# a34m41x register map
Vendor: ABOV Semiconductor Co., Ltd.; File version: 1.0
CPU: CM4 r0p1, little endian, MPU, FPU, VTOR, 4 interrupt priority bits
Registers are 32-bit, read-write, reset 0x0 unless marked. A register's access mark holds for its fields unless they carry their own. Offsets are from the block's base; [hi:lo] are bit positions; {n}, {i} and the like mark numbered series; 'fields as' and 'values as' point back to an identical list.

## QEI0 — Quadurature Encoder Interface
Base 0x4000B400
Same registers: QEI1 0x4000B500
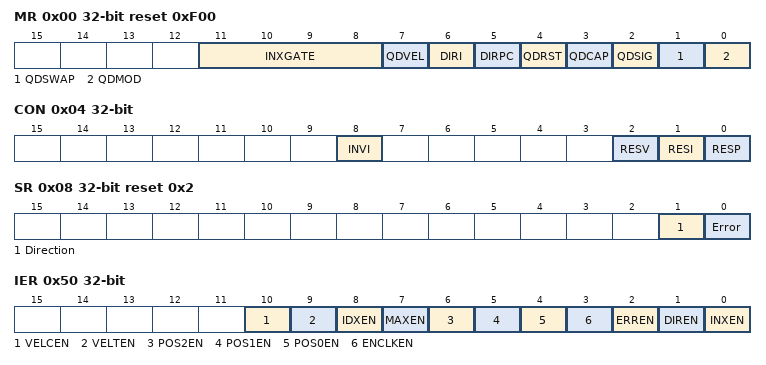
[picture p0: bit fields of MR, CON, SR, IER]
0x00 MR reset 0xF00 — QEI n Mode Register
  [11:8] INXGATE — Index Gating Configuration
    15=ALL_PASS (Pass the index); 8=PhA_0_PhB_0 (Pass the index when Ph-A = 0, Ph-B = 0); 4=PhA_0_PhB_1 (Pass the index when Ph-A = 0, Ph-B = 1); 2=PhA_1_PhB_1 (Pass the index when Ph-A = 1, Ph-B = 1); 1=PhA_1_PhB_0 (Pass the index when Ph-A = 1, Ph-B = 0)
  [7] QDVEL — Velocity Counter Enable Bit
    0=Disable; 1=Enable
  [6] DIRI — Index Counter Direction Control bit
    0=Not_Affect (DI Status Not Affect to the counter); 1=Change_Direction (DIR Status Will Change Count Direction)
  [5] DIRPC — Position Counter Direction Control bit
    values as DIRI
  [4] QDRST — Reset Mode Setting Bit
    0=Maximum_Position (Reset With Maximum Position Reset); 1=Index_Pulse (Reset with index pulse)
  [3] QDCAP — Capture Mode Setting Bit
    0=Only Ph-A Edge is Counted; 1=PhA_PhB (Ph-A and Ph-B Edge are counted)
  [2] QDSIG — Signal Mode Setting Bit
    0=Quadrature phase signal (Ph-A, Ph-B); 1=Clock_Direction (Clock Signal = Ph-A, Direction Signal = Ph-B)
  [1] QDSWAP — QEI Input Signal SWAP Setting Bit
    0=No_Swap; 1=Swap Ph-A and Ph-B
  [0] QDMOD — QEI Module Enable Bit
    0=Disable; 1=Enable
0x04 CON — QEI n Control Register
  [8] INVI — Index Pulse Reverse Setting Bit
    0=None; 1=Reverse (Index Input Pulse Reverse)
  [2] RESV — Velocity Counter Init Bit
    0=None; 1=Init (Velocity Counter Init)
  [1] RESI — Index Counter Init Bit
    0=None; 1=Init (Index Counter Init)
  [0] RESP — Position Counter Init Bit
    0=None; 1=Init (Position Counter Init)
0x08 SR reset 0x2 — QEI n Status Register
  [1] Direction — Direction Status Bit
    0=Reverse (Direction is reverse); 1=Positive (Direction is positive)
  [0] Error — Error was detected in the gray code sequence
0x0C POS — QEI n Position Counter Register
  [31:0] QEIPOS — Current Position Counter Value
0x10 MAX reset 0xFFFFFFFF — QEI n Position Counter Maximum Register
  [31:0] QEIMAX — Position Counter Maximum Value Setting Bit
{0x14+4i} CMP{i} reset 0xFFFFFFFF (i=0..2) — QEI n Position Counter Compare{i} Register
  [31:0] QEICMP{i} — Position Compare{i} Value Setting Bit
0x20 IDX — QEI n Index Counter Register
  [15:0] QEIIDX — Current Index Counter Value
0x24 CMPI reset 0xFFFF — QEI n Index Comapre Register
  [15:0] QEICMPI — Index Counter Compare Value Setting Bit
0x30 VLR reset 0xFFFF — QEI n Velocity Reload Register
  [15:0] QEIVLR — Velocity Timer Reload Value Bit
0x34 VLT reset 0xFFFF — QEI n Velocity Timer Register
  [15:0] QEIVLT — Current Velocity Timer Value Bit
0x38 VLP — QEI n Velocity Pulse Counter Register
  [15:0] QEIVLP — Current Velocity Pulse Counter Value Bit
0x3C VLC reset 0xFFFF — QEI n Velocity Capture Register
  [15:0] QEIVLC — Velocity Capture Value Register
0x40 VLCOM — QEI n Velocity Compare Value Register
  [15:0] QEIVLCOM — Velocity Compare Value Register
0x50 IER — QEI n Interrupt Enable Register
  [all] fields
    0=Disable; 1=Enable
  [10] VELCEN — Interrupt when a capture value smaaler than the velocity comparison value is input
  [9] VELTEN — Interrupt when velocity timer value is '0'
  [8] IDXEN — Interrupt when Index counter same as Index comparison value
  [7] MAXEN — Interrupt when position counter is maximum value (setting value)
  [6] POS2EN — Position 2 Interrupt when compare value register and current counter value are the same
  [5] POS1EN — Position 1 Interrupt when compare value register and current counter value are the same
  [4] POS0EN — Position 0 Interrupt when compare value register and current counter value are the same
  [3] ENCLKEN — Decoder Clock Pulse Occurred Flag Enable Bit
  [2] ERREN — Decoder Phase Error Occurred Flag Enable Bit
  [1] DIREN — Direction Change Occurred Flag Enable bit
  [0] INXEN — Index Pulse Occurred Flag Enable bit
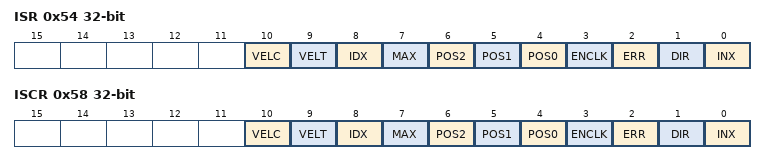
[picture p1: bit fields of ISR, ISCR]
0x54 ISR ro — QEI n Interrupt Status Register
  [10] VELC — Flag when a capture value smaaler than the velocity comparison value is input
  [9] VELT — Flag when velocity timer value is '0'
  [8] IDX — Flag when Index counter same as Index comparison value
  [7] MAX — Flag when position counter is maximum value (setting value)
  [6] POS2 — Position 2 Flag when compare value register and current counter value are the same
  [5] POS1 — Position 1 Flag when compare value register and current counter value are the same
  [4] POS0 — Position 0 Flag when compare value register and current counter value are the same
  [3] ENCLK — Decoder Clock Pulse Occurred Flag Bit
  [2] ERR — Decoder Phase Error Occurred Flag Bit
  [1] DIR — Direction Change Occurred Flag bit
  [0] INX — Index Pulse Occurred Flag bit
0x58 ISCR wo — QEI n Interrupt Status Clear Register
  [10] VELC — Flag Clear when a capture value smaaler than the velocity comparison value is input
  [9] VELT — Flag Clear when velocity timer value is '0'
  [8] IDX — Flag Clear when Index counter same as Index comparison value
  [7] MAX — Flag Clear when position counter is maximum value (setting value)
  [6] POS2 — Position 2 Flag Clear when compare value register and current counter value are the same
  [5] POS1 — Position 1 Flag Clear when compare value register and current counter value are the same
  [4] POS0 — Position 0 Flag Clear when compare value register and current counter value are the same
  [3] ENCLK — Decoder Clock Pulse Occurred Flag Clear Bit
  [2] ERR — Decoder Phase Error Occurred Flag Clear Bit
  [1] DIR — Direction Change Occurred Flag Clear bit
  [0] INX — Index Pulse Occurred Flag Clear bit
